# SERDES_10G0 register map
Vendor: Texas Instruments
Registers are 32-bit, read-write, reset 0x0 unless marked. A register's access mark holds for its fields unless they carry their own. Offsets are as the file gives them; [hi:lo] are bit positions; {n}, {i} and the like mark numbered series.

## SERDES_10G0 (part 2 of 5)
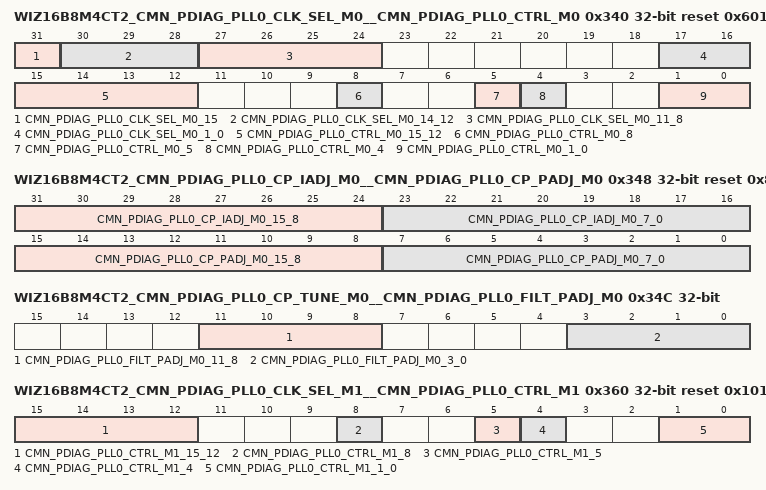
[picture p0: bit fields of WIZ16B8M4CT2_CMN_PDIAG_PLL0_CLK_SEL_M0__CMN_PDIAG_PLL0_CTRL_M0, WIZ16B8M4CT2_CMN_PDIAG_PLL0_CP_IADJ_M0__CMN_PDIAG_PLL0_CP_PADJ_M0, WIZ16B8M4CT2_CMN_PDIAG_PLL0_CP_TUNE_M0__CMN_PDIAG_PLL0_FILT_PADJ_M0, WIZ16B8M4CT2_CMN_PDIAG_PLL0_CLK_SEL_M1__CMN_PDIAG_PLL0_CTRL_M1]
0x340 WIZ16B8M4CT2_CMN_PDIAG_PLL0_CLK_SEL_M0__CMN_PDIAG_PLL0_CTRL_M0 reset 0x6011012 — PLL 0 control register mode 0
  [31] CMN_PDIAG_PLL0_CLK_SEL_M0_15 — PLL 0 clock 1 divider enable: This bit enables the divider used to generate the cmnda_pll0_clk_1, from the PLL high speed clock.
  [30:28] CMN_PDIAG_PLL0_CLK_SEL_M0_14_12 — PLL 0 clock 1 divider select: This field selects the divider value used to generate the cmnda_pll0_clk_1, from the PLL high speed clock, by driving the cmnda_pll0_clk_1_div_sel signal to the analog. The encoding of this signal is as follows. All codes currently result in divide by 16.
  [27:24] CMN_PDIAG_PLL0_CLK_SEL_M0_11_8 — PLL 0 clock 0 and derived reference clock divider select: This field selects the divider value used to generate the cmnda_pll0_clk_0 and derived reference clock, from the PLL high speed clock, by driving the cmnda_pll0_clk_0_div_sel signal to the analog. The encoding of this signal is as follows. Note that there are different divider values per bit for associated with each clock.
  [17:16] CMN_PDIAG_PLL0_CLK_SEL_M0_1_0 — PLL 0 clock select: This field selects one of 3 possible high speed output clocks from PLL 0, to drive on the high speed analog clock 0, by driving the cmnda_pll0_clk_sel signal to the analog. The encoding for this is as follows. 2'b00: Divide by 1 2'b01: Divide by 2 2'b10: Divide by 4 2'b11: Reserved
  [15:12] CMN_PDIAG_PLL0_CTRL_M0_15_12 — This field controls the Ring VCO Frequency drift with temperature. It controls the mix of vtref bias and external bias to keep the temperature drift for the ring low, by driving the cmnda_pll0_vco_ring_cmos_sel signal going into the common analog.
  [8] CMN_PDIAG_PLL0_CTRL_M0_8 — PLL VCO select: Selects the VCO mode of operation, by driving the cmnda_pll0_vco_sel signal going into the common analog. 1'b0: LC tank mode 1'b1: Ring oscillator mode
  [5] CMN_PDIAG_PLL0_CTRL_M0_5 — PLL feedback divider clock select: This signal selects which internal PLL clock will be used to drive the cmnda_pll0_fb_divider_clk, by driving the cmnda_pll0_fb_divider_clk_sel signal going into the common analog. 1'b0: Feedback divider clock 1'b1: PLL digital rate clock
  [4] CMN_PDIAG_PLL0_CTRL_M0_4 — PLL feedback divider pre-scale: controls the feedback divider pre-scale, by driving the cmnda_pll0_div24_sel signal going into the common analog. One should read the description of the PLL in section 10.4 Dual VCO PLL on page 420 for detailed information about the function of this divider control. 1'b0: Divide by 2 - When using the delta sigma modulator, this setting results in lower noise on the PLL output clock, but higher power. 1'b1: Divide by 4 - When using the delta sigma modulator, this setting results in higher noise on the PLL output clock, but lower power. This setting is ideal for cases when the delta sigma modulator is not used, because is results in both lower noise and lower power.
  [1:0] CMN_PDIAG_PLL0_CTRL_M0_1_0 — PLL PFD reset delay: Controls the minimum reset pulse width for the PFD. This drives the cmnda_pll0_pfd_rst_dly signal going into the common analog. The following lists the reset pulse width values for typical conditions for each of the possible values for this field. 2'b00 : Delay = 257.5 pSec (minimum) 2'b01 : Delay = 337.4 pSec 2'b10 : Delay = 415.2 pSec 2'b11 : Delay = 493.2 pSec (maximum)
0x348 WIZ16B8M4CT2_CMN_PDIAG_PLL0_CP_IADJ_M0__CMN_PDIAG_PLL0_CP_PADJ_M0 reset 0x8080028 — PLL 0 charge pump proportional path adjust register mode 0
  [31:24] CMN_PDIAG_PLL0_CP_IADJ_M0_15_8 — PLL charge pump integral path capacitance adjust: Adjusts the charge pump integral path capacitance, by driving the cmnda_pll0_cp_int_cap_adj signal going to the analog.
  [23:16] CMN_PDIAG_PLL0_CP_IADJ_M0_7_0 — PLL charge pump integral path current adjust: Adjusts the charge pump integral path current, by driving the cmnda_pll0_cp_int_cur_adj signal going to the analog.
  [15:8] CMN_PDIAG_PLL0_CP_PADJ_M0_15_8 — PLL charge pump proportional path capacitance adjust: Adjusts the charge pump proportional path capacitance, by driving the cmnda_pll0_cp_prop_cap_adj signal going to the analog.
  [7:0] CMN_PDIAG_PLL0_CP_PADJ_M0_7_0 — PLL charge pump proportional path current adjust: Adjusts the charge pump proportional path current, by driving the cmnda_pll0_cp_prop_cur_adj signal going to the analog.
0x34C WIZ16B8M4CT2_CMN_PDIAG_PLL0_CP_TUNE_M0__CMN_PDIAG_PLL0_FILT_PADJ_M0 — PLL 0 proportional path filter adjust register mode 0
  [11:8] CMN_PDIAG_PLL0_FILT_PADJ_M0_11_8 — PLL proportional path filter capacitance adjust: Adjusts the proportional path filter capacitance, by driving the cmnda_pll0_filt_c_adj signal going to the analog.
  [3:0] CMN_PDIAG_PLL0_FILT_PADJ_M0_3_0 — PLL proportional path filter resistance adjust: Adjusts the proportional path filter resistance, by driving the cmnda_pll0_filt_r_adj signal going to the analog.
0x360 WIZ16B8M4CT2_CMN_PDIAG_PLL0_CLK_SEL_M1__CMN_PDIAG_PLL0_CTRL_M1 reset 0x1012 — PLL 0 control register mode 1
  [15:12] CMN_PDIAG_PLL0_CTRL_M1_15_12 — This field controls the Ring VCO Frequency drift with temperature. It controls the mix of vtref bias and external bias to keep the temperature drift for the ring low, by driving the cmnda_pll0_vco_ring_cmos_sel signal going into the common analog.
  [8] CMN_PDIAG_PLL0_CTRL_M1_8 — PLL VCO select: Selects the VCO mode of operation, by driving the cmnda_pll0_vco_sel signal going into the common analog. 1'b0: LC tank mode 1'b1: Ring oscillator mode
  [5] CMN_PDIAG_PLL0_CTRL_M1_5 — PLL feedback divider clock select: This signal selects which internal PLL clock will be used to drive the cmnda_pll0_fb_divider_clk,driving the cmnda_pll0_fb_divider_clk_sel signal going into the common analog. 1'b0: Feedback divider clock 1'b1: PLL digital rate clock
  [4] CMN_PDIAG_PLL0_CTRL_M1_4 — PLL feedback divider pre-scale: controls the feedback divider pre-scale, by driving the cmnda_pll0_div24_sel signal going into the common analog. One should read the description of the PLL in section 10.4 Dual VCO PLL on page 420 for detailed information about the function of this divider control. 1'b0: Divide by 2 - When using the delta sigma modulator, this setting results in lower noise on the PLL output clock, but higher power. 1'b1: Divide by 4 - When using the delta sigma modulator, this setting results in higher noise on the PLL output clock, but lower power. This setting is ideal for cases when the delta sigma modulator is not used, because is results in both lower noise and lower power.
  [1:0] CMN_PDIAG_PLL0_CTRL_M1_1_0 — PLL PFD reset delay: Controls the minimum reset pulse width for the PFD. This drives the cmnda_pll0_pfd_rst_dly signal going into the common analog. The following lists the reset pulse width values for typical conditions for each of the possible values for this field. 2'b00 : Delay = 257.5 pSec (minimum) 2'b01 : Delay = 337.4 pSec 2'b10 : Delay = 415.2 pSec 2'b11 : Delay = 493.2 pSec (maximum)
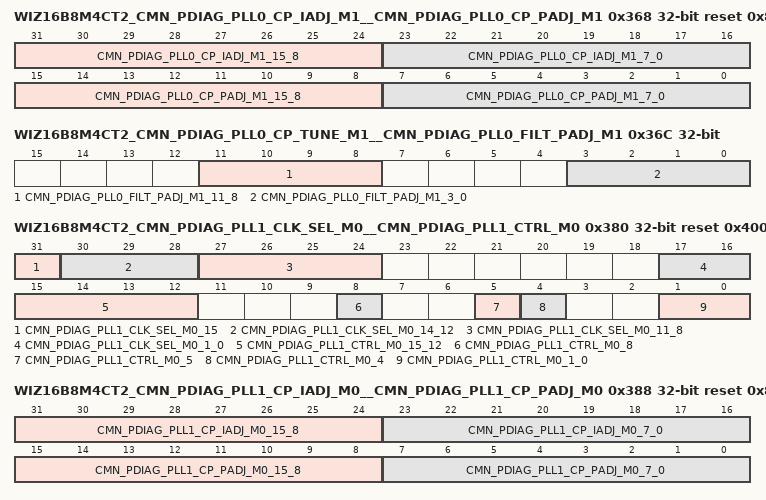
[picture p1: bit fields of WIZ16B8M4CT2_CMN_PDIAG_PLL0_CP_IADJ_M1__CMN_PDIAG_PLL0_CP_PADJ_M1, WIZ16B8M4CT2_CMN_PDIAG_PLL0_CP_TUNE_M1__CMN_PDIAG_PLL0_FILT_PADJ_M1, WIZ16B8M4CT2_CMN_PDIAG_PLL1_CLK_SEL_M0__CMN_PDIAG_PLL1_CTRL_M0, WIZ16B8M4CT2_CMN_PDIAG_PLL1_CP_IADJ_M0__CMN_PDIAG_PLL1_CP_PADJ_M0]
0x368 WIZ16B8M4CT2_CMN_PDIAG_PLL0_CP_IADJ_M1__CMN_PDIAG_PLL0_CP_PADJ_M1 reset 0x8080128 — PLL 0 charge pump proportional path adjust register mode 1
  [31:24] CMN_PDIAG_PLL0_CP_IADJ_M1_15_8 — PLL charge pump integral path capacitance adjust: Adjusts the charge pump integral path capacitance, by driving the cmnda_pll0_cp_int_cap_adj signal going to the analog.
  [23:16] CMN_PDIAG_PLL0_CP_IADJ_M1_7_0 — PLL charge pump integral path current adjust: Adjusts the charge pump integral path current, by driving the cmnda_pll0_cp_int_cur_adj signal going to the analog.
  [15:8] CMN_PDIAG_PLL0_CP_PADJ_M1_15_8 — PLL charge pump proportional path capacitance adjust: Adjusts the charge pump proportional path capacitance, by driving the cmnda_pll0_cp_prop_cap_adj signal going to the analog.
  [7:0] CMN_PDIAG_PLL0_CP_PADJ_M1_7_0 — PLL charge pump proportional path current adjust: Adjusts the charge pump proportional path current, by driving the cmnda_pll0_cp_prop_cur_adj signal going to the analog.
0x36C WIZ16B8M4CT2_CMN_PDIAG_PLL0_CP_TUNE_M1__CMN_PDIAG_PLL0_FILT_PADJ_M1 — PLL 0 proportional path filter adjust register mode 1
  [11:8] CMN_PDIAG_PLL0_FILT_PADJ_M1_11_8 — PLL proportional path filter capacitance adjust: Adjusts the proportional path filter capacitance, by driving the cmnda_pll0_filt_c_adj signal going to the analog.
  [3:0] CMN_PDIAG_PLL0_FILT_PADJ_M1_3_0 — PLL proportional path filter resistance adjust: Adjusts the proportional path filter resistance, by driving the cmnda_pll0_filt_r_adj signal going to the analog.
0x380 WIZ16B8M4CT2_CMN_PDIAG_PLL1_CLK_SEL_M0__CMN_PDIAG_PLL1_CTRL_M0 reset 0x4001012 — PLL 1 control register mode 0
  [31] CMN_PDIAG_PLL1_CLK_SEL_M0_15 — PLL 1 clock 1 divider enable: This bit enables the divider used to generate the cmnda_pll1_clk_1, from the PLL high speed clock.
  [30:28] CMN_PDIAG_PLL1_CLK_SEL_M0_14_12 — PLL 1 clock 1 divider select: This field selects the divider value used to generate the cmnda_pll1_clk_1, from the PLL high speed clock, by driving the cmnda_pll1_clk_1_div_sel signal to the analog. The encoding of this signal is as follows. All codes currently result in divide by 16.
  [27:24] CMN_PDIAG_PLL1_CLK_SEL_M0_11_8 — PLL 1 clock 0 and derived reference clock divider select: This field selects the divider value used to generate the cmnda_pll1_clk_0 and derived reference clock, from the PLL high speed clock, by driving the cmnda_pll1_clk_0_div_sel signal to the analog. The encoding of this signal is as follows. Note that there are different divider values per bit for associated with each clock.
  [17:16] CMN_PDIAG_PLL1_CLK_SEL_M0_1_0 — PLL 1 clock select: This field selects one of 3 possible high speed output clocks from PLL 1, to drive on the high speed analog clock 1, by driving the cmnda_pll1_clk_sel signal to the analog. The encoding for this is as follows. 2'b00: Divide by 1 2'b01: Divide by 2 2'b10: Divide by 4 2'b11: Reserved
  [15:12] CMN_PDIAG_PLL1_CTRL_M0_15_12 — This field controls the Ring VCO Frequency drift with temperature. It controls the mix of vtref bias and external bias to keep the temperature drift for the ring low, by driving the cmnda_pll1_vco_ring_cmos_sel signal going into the common analog.
  [8] CMN_PDIAG_PLL1_CTRL_M0_8 — PLL VCO select: Selects the VCO mode of operation, by driving the cmnda_pll1_vco_sel signal going into the common analog. 1'b0: LC tank mode 1'b1: Ring oscillator mode
  [5] CMN_PDIAG_PLL1_CTRL_M0_5 — PLL feedback divider clock select: This signal selects which internal PLL clock will be used to drive the cmnda_pll1_fb_divider_clk,driving the cmnda_pll1_fb_divider_clk_sel signal going into the common analog. 1'b0: Feedback divider clock 1'b1: PLL digital rate clock
  [4] CMN_PDIAG_PLL1_CTRL_M0_4 — PLL feedback divider pre-scale: controls the feedback divider pre-scale, by driving the cmnda_pll1_div24_sel signal going into the common analog. One should read the description of the PLL in section 10.4 Dual VCO PLL on page 420 for detailed information about the function of this divider control. 1'b0: Divide by 2 - When using the delta sigma modulator, this setting results in lower noise on the PLL output clock, but higher power. 1'b1: Divide by 4 - When using the delta sigma modulator, this setting results in higher noise on the PLL output clock, but lower power. This setting is ideal for cases when the delta sigma modulator is not used, because is results in both lower noise and lower power.
  [1:0] CMN_PDIAG_PLL1_CTRL_M0_1_0 — PLL PFD reset delay: Controls the minimum reset pulse width for the PFD. This drives the cmnda_pll1_pfd_rst_dly signal going into the common analog. The following lists the reset pulse width values for typical conditions for each of the possible values for this field. 2'b00 : Delay = 257.5 pSec (minimum) 2'b01 : Delay = 337.4 pSec 2'b10 : Delay = 415.2 pSec 2'b11 : Delay = 493.2 pSec (maximum)
0x388 WIZ16B8M4CT2_CMN_PDIAG_PLL1_CP_IADJ_M0__CMN_PDIAG_PLL1_CP_PADJ_M0 reset 0x8080128 — PLL 1 charge pump proportional path adjust register mode 0
  [31:24] CMN_PDIAG_PLL1_CP_IADJ_M0_15_8 — PLL charge pump integral path capacitance adjust: Adjusts the charge pump integral path capacitance, by driving the cmnda_pll1_cp_int_cap_adj signal going to the analog.
  [23:16] CMN_PDIAG_PLL1_CP_IADJ_M0_7_0 — PLL charge pump integral path current adjust: Adjusts the charge pump integral path current, by driving the cmnda_pll1_cp_int_cur_adj signal going to the analog.
  [15:8] CMN_PDIAG_PLL1_CP_PADJ_M0_15_8 — PLL charge pump proportional path capacitance adjust: Adjusts the charge pump proportional path capacitance, by driving the cmnda_pll1_cp_prop_cap_adj signal going to the analog.
  [7:0] CMN_PDIAG_PLL1_CP_PADJ_M0_7_0 — PLL charge pump proportional path current adjust: Adjusts the charge pump proportional path current, by driving the cmnda_pll0_cp_prop_cur_adj signal going to the analog.
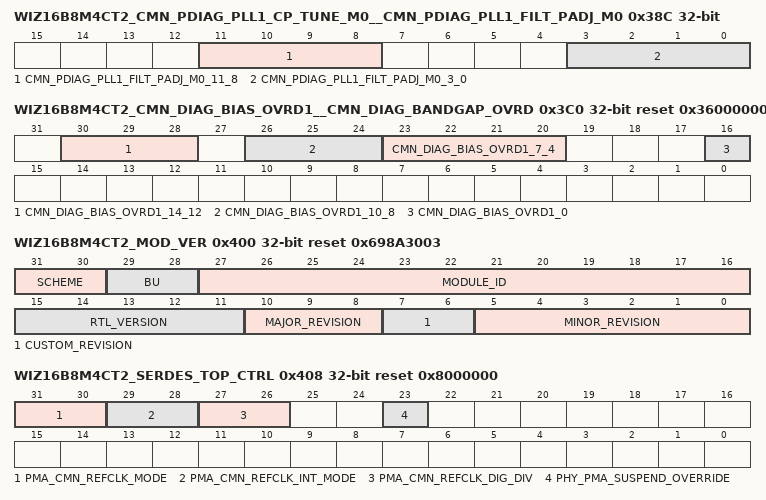
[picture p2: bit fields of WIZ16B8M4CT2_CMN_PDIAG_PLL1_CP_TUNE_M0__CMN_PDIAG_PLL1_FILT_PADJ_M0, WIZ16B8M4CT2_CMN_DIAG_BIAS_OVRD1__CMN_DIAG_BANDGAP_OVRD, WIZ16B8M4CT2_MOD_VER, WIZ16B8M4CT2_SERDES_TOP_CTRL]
0x38C WIZ16B8M4CT2_CMN_PDIAG_PLL1_CP_TUNE_M0__CMN_PDIAG_PLL1_FILT_PADJ_M0 — PLL 1 proportional path filter adjust register mode 0
  [11:8] CMN_PDIAG_PLL1_FILT_PADJ_M0_11_8 — PLL proportional path filter capacitance adjust: Adjusts the proportional path filter capacitance, by driving the cmnda_pll1_filt_c_adj signal going to the analog.
  [3:0] CMN_PDIAG_PLL1_FILT_PADJ_M0_3_0 — PLL proportional path filter resistance adjust: Adjusts the proportional path filter resistance, by driving the cmnda_pll1_filt_r_adj signal going to the analog.
0x3C0 WIZ16B8M4CT2_CMN_DIAG_BIAS_OVRD1__CMN_DIAG_BANDGAP_OVRD reset 0x36000000 — Bandgap override register
  [30:28] CMN_DIAG_BIAS_OVRD1_14_12 — Receiver resistor calibration current adjust: This field is used to adjust the receiver resistor calibration bias current. It drives the cmnda_bias_rx_rescal_adj signal going to the analog. The following list shows the encoding of this field. 3'b000 : 110.72 uA 3'b001 : 112.50 uA 3'b010 : 114.29 uA 3'b011 : 116.07 uA 3'b100 : 117.86 uA 3'b101 : 119.64 uA 3'b110 : 121.43 uA 3'b111 : 123.22 uA
  [26:24] CMN_DIAG_BIAS_OVRD1_10_8 — Transmitter resistor calibration current adjust: This field is used to adjust the transmitter resistor calibration bias current. It drives the cmnda_bias_tx_rescal_adj signal going to the analog. The following list shows the encoding of this field. 3'b000 : 110.72 uA 3'b001 : 112.50 uA 3'b010 : 114.29 uA 3'b011 : 116.07 uA 3'b100 : 117.86 uA 3'b101 : 119.64 uA 3'b110 : 121.43 uA 3'b111 : 123.22 uA
  [23:20] CMN_DIAG_BIAS_OVRD1_7_4 — Reserved - spare
  [16] CMN_DIAG_BIAS_OVRD1_0 — Reserved - spare
0x400 WIZ16B8M4CT2_MOD_VER ro reset 0x698A3003 — The Module and Version Register identifies the module identifier and revision of the WIZ16B8M4CT2 module.
  [31:30] SCHEME — Module Scheme
  [29:28] BU — Module Business Unit
  [27:16] MODULE_ID — WIZ16B8M4CT2 module ID.
  [15:11] RTL_VERSION
  [10:8] MAJOR_REVISION
  [7:6] CUSTOM_REVISION
  [5:0] MINOR_REVISION
0x404 WIZ16B8M4CT2_SERDES_CTRL — Sets the SERDES control state.
  [31] POR_EN — The por_en allows the system to place the SERDES in a reset state, Access to the SERDES registers are ignored.
0x408 WIZ16B8M4CT2_SERDES_TOP_CTRL reset 0x8000000 — The SERDES Top Level Control
  [31:30] PMA_CMN_REFCLK_MODE — The PMA common differential reference clock mode - Sets the mode of operation for differential reference clock input. Must be set before the de-assertion of apb_preset_n/phy_reset_n. 2'b00 - 100 MHz and greater differential reference clock. 2'b01 - 100 MHz and greater singled ended DC coupled test reference clock. 2'b10 - Less than 100 MHz differential reference clock. 2'b11 - Less than 100 MHz single ended DC coupled test reference clock.
  [29:28] PMA_CMN_REFCLK_INT_MODE — The PMA common internal reference clock mode - Sets the mode of operation for internal reference clock input. Must be set before the de-assertion of apb_preset_n/phy_reset_n. 2'b00 - Reserved 2'b01 - 100 MHz and greater reference clock 2'b10 - Reserved 2'b11 - Less than 100 MHz reference clock
  [27:26] PMA_CMN_REFCLK_DIG_DIV — The PMA common reference clock digital divide ratio select - Must be set before the de-assertion of apb_preset_n/phy_reset_n. 2'b00 - Divide by 1 (set for reference clock in the 19.2 to 27MHz range) 2'b01 - Divide by 2 (Reserved) 2'b10 - Divide by 4 (set for 100 MHz reference clock) 2'b11 - Divide by 8 (Reserved)
  [23] PHY_PMA_SUSPEND_OVERRIDE — The PHY PMA common suspend override enable: 1 = disables suspending the PMA common when all links are in low power state (L1 SS, PCIe P2, USB P3, power down disabled, etc.). 0 = PMA common will be suspended when all links are in low power state. Driving this pin high has no effect if the PMA common is already suspended or is in the process of being suspended (i.e. it will not force the PMA common to resume). It only prevents the start of suspending the PMA common. However, if this pin is de-asserted when all links are in low power state, the PMA common will then be suspended.
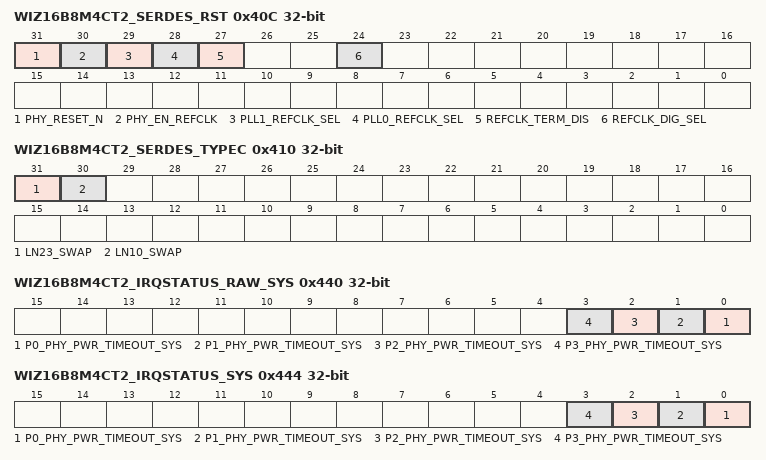
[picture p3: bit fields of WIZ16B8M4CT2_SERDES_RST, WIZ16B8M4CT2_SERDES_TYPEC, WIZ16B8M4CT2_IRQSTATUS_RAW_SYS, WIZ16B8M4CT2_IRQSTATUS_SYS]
0x40C WIZ16B8M4CT2_SERDES_RST — The SERDES Reset Register controls the Phy reset and REFCLK selection for the SERDES.
  [31] PHY_RESET_N — The PHY reset : Asserting this signal low will reset all PHY logic for the entire PHY with the exception of the APB registers and TAP controller. Note: Upon de-assertion, all PHY inputs must be driven as described in the PIPE specification for a PIPE reset.
  [30] PHY_EN_REFCLK — The PHY reference clock enable: When cmn_refclk_<p/m> is configured as a reference clock output, 1 = glitch-less enable of the reference clock output. 0 = glitch-less turn off reference clock output. Used in L1.x entry/exit protocol. Note: When outputting a derived reference clock from the PLL, it is recommended to drive phy_en_refclk low until the PHY has completed start-up and de-asserted pipe_l*_reset_ n for PIPE operation or asserted cmn_ready for Raw SERDES operation.. The clock will not be 'good' until the PHY has completed initial start-up.
  [29] PLL1_REFCLK_SEL — The PMA common PLL1 reference clock source select - 0 - Selects cmn_refclk_<m/p> as reference clock source 1 - Selects pma_cmn_refclk_int as reference clock source. Note: This field is write protected when register field ~iphy_reset_n is a '1'.
  [28] PLL0_REFCLK_SEL — The PMA common PLL0 reference clock source select - 0 - Selects cmn_refclk_<m/p> as reference clock source 1 - Selects pma_cmn_refclk_int as reference clock source. Note: This field is write protected when register field ~iphy_reset_n is a '1'.
  [27] REFCLK_TERM_DIS — The PMA common differential reference clock termination disable - enables/disables termination for difference reference clock input (cmn_refclk_<p/m>). Must be set before the de-assertion of apb_preset_n/phy_reset_n. 1 = termination disabled 0 = termination enabled. Note: This field is write protected when register field ~iphy_reset_n is a '1'.
  [24] REFCLK_DIG_SEL — The PMA common reference clock select - Selects the reference clock source for the digital logic between cmn_refclk_<p/m> and pma_cmn_refclk_int. Must be set before the de-assertion of apb_preset_n/phy_reset_n. 0 - cmn_refclk_<p/m> 1 - pma_cmn_refclk_int. Note: This field is write protected when register field ~iphy_reset_n is a '1'.
0x410 WIZ16B8M4CT2_SERDES_TYPEC — The SERDES Type C control register allows the external lanes selection to be swapped.
  [31] LN23_SWAP — The~iln23_swap will swap the lanes 2 and 3. That is all control for lane 2 will apply to lane 3 and vice versa. You cannot set ~iln23_swap to swap lanes in a link. That is If lanes 2 and 3 are used for a single link of PCIe, the ~iln23_swap must be '0'. Note: This field is write protected when register field ~i(reg_p2_enable|reg_p3_enable) is a '1'.
  [30] LN10_SWAP — The ~iln10_swap will swap the lanes 0 and 1. That is all control for lane 0 will apply to lane 1 and vice versa. You cannot set ~iln10_swap to swap lanes in a link. That is If lanes 0 and 1 are used for a single link of PCIe, the ~iln10_swap must be '0'. Note: This field is write protected when register field ~i(reg_p0_enable|reg_p1_enable) is a '1'.
0x440 WIZ16B8M4CT2_IRQSTATUS_RAW_SYS access not given — The System Interrupt Raw Status Register holds the raw status of the SERDES power timout interrupts.
  [n] P{n}_PHY_PWR_TIMEOUT_SYS (n=0..3) — Phy Power Timeout occured for lane {n} error. That is the lane power state took too long to occur.. Write 1 to clear the status after interrupt has been serviced (raw status gets cleared, i.e. even if not enabled). Writing a 0 has no effect. (access R/W1TS)
0x444 WIZ16B8M4CT2_IRQSTATUS_SYS access not given — The System Interrupt Status Register holds the masked status for the SERDES power timout interrupts.
  [n] P{n}_PHY_PWR_TIMEOUT_SYS (n=0..3) — Phy Power Timeout occured for lane {n} error. That is the lane power state took too long to occur.. Write 1 to clear the status after interrupt has been serviced (raw status gets cleared, i.e. even if not enabled). Writing a 0 has no effect. (access R/W1TC)
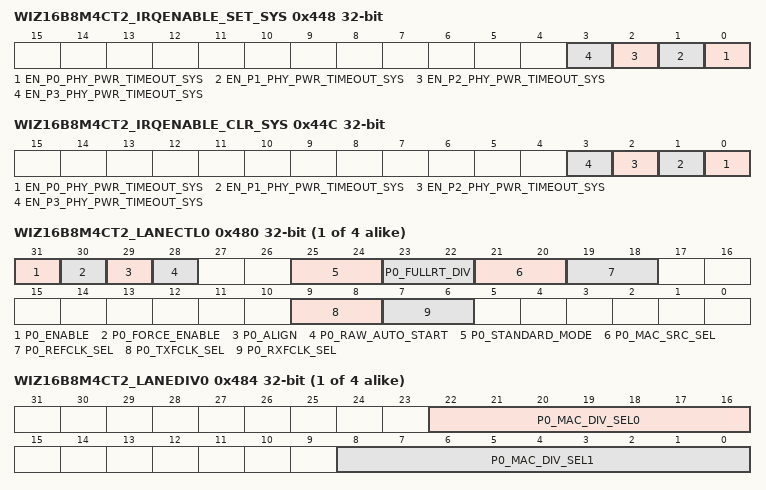
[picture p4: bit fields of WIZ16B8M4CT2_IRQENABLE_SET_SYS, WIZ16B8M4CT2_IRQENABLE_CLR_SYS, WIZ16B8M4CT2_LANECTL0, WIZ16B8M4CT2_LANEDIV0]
0x448 WIZ16B8M4CT2_IRQENABLE_SET_SYS access not given — The System Interrupt Enable Set Register holds the interrupt enable status of the SERDES power timout interrupts.
  [n] EN_P{n}_PHY_PWR_TIMEOUT_SYS (n=0..3) — Interrupt Enable set for Phy Power Timeout for lane {n} error. Writing a 1 will enable the interrupt, and set this bit as well as the corresponding Interrupt Enable Set Register. Writing a 0 has no effect. (access R/W1TS)
0x44C WIZ16B8M4CT2_IRQENABLE_CLR_SYS access not given — The System Interrupt Enable Clear Register holds the interrupt enable status of the SERDES power timout interrupts.
  [n] EN_P{n}_PHY_PWR_TIMEOUT_SYS (n=0..3) — Interrupt Enable clear for Phy Power Timeout for lane {n} error. Writing a 1 will disable the interrupt, and clear this bit as well as the corresponding Interrupt Enable Set Register. Writing a 0 has no effect. (access R/W1TC)
{0x480+0x40*i} WIZ16B8M4CT2_LANECTL{i} (i=0..3) — The Lane Control Register sets the lane specific modes of operation.
  [31] P{i}_ENABLE — The p{i}_enable is AND'd with the IPx_LNy_reset_n to enable the lane.
  [30] P{i}_FORCE_ENABLE — The p{i}_force_enable is OR'd with the IPx_LNy_reset_n to force enable the lane.
  [29] P{i}_ALIGN — The p{i}_align will auto align the RAW interface to 8B10B comma characters.
  [28] P{i}_RAW_AUTO_START — The p{i}_raw_auto_start will auto sequence the RAW interface according to the configuration settings
  [25:24] P{i}_STANDARD_MODE — Standard Mode specified by Cadence.
  [23:22] P{i}_FULLRT_DIV — Full Rate divider for 2x MAC speed mode. The PMA PLL full rate clock divider select - divide ratio for pma_pllclk_fullrt_ln_*. 00 = Divide by 1 01 = Divide by 2 10 = Divide by 4 11 = Divide by 8
  [21:20] P{i}_MAC_SRC_SEL — MAC clock source select : Selects which PMA clock to use as clock souse for pcs_mac_clk*_ln_*. 2'b00 - PMA output xcvr_pll_clk_datart_ln_* for the associated lane. 2'b01 - PMA output xcvr_pll_clk_fullrt_ln_* for the associated lane. 2'b10 - PMA output cmn_ref_clk_rcv. 2'b11 - Reserved
  [19:18] P{i}_REFCLK_SEL — Refclk Select determines which clocks will be used for the IP refclk signal. 0 - pma_pllclk_fullrt_ln_{i} is used. 1 - pcs_mac_clk_ln_{i} is used. 2 - pcs_mac_clk_divx0_ln_{i} is used. 3 - pcs_mac_clk_divx1_ln_{i} is used.
  [9:8] P{i}_TXFCLK_SEL — Fclk Select determines which clocks will be used for the IP txfclk signal. 0 - pma_pllclk_fullrt_ln_{i} is used. 1 - pcs_mac_clk_ln_{i} is used. 2 - pcs_mac_clk_divx0_ln_{i} is used. 3 - pcs_mac_clk_divx1_ln_{i} is used.
  [7:6] P{i}_RXFCLK_SEL — Fclk Select determines which clocks will be used for the IP rxfclk signal. 0 - pma_rx_rd_clk2x_ln_{i} is used. 1 - pma_rx_rd_clk_ln_{i} is used. 2 - rd_div2_clk{i} is used. 3 - rd_div4_clk{i} is used.
{0x484+0x40*i} WIZ16B8M4CT2_LANEDIV{i} (i=0..3) — The Lane Divider Register sets the lane specific dividers of
  [22:16] P{i}_MAC_DIV_SEL0 — The ~ip{i}_mac_div_sel0 controls the divider for lane {i} MAC clock divider ratio select : Selects the divider ratio for pcs_mac_clk_divx0_ln_*. 7'd0 : Reserved 7'd1 : Divide by 1 7'd2 : Divide by 2 7'd3 : Divide by 3 ... 7'dn : Divide by n n = 127 (maximum)
  [8:0] P{i}_MAC_DIV_SEL1 — The ~ip{i}_mac_div_sel1 controls the divider for lane {i} MAC clock divider ratio select : Selects the divider ratio for pcs_mac_clk_divx1_ln_*. 9'd0 : Reserved 9'd1 : Divide by 1 9'd2 : Divide by 2 9'd3 : Divide by 3 ... 9'dn : Divide by n n = 511 (maximum)
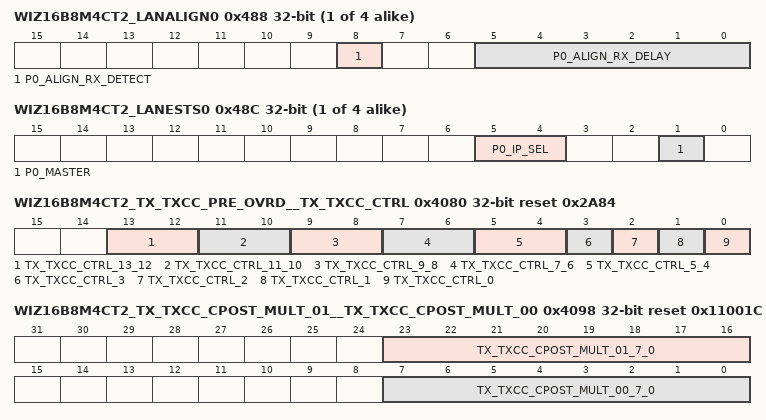
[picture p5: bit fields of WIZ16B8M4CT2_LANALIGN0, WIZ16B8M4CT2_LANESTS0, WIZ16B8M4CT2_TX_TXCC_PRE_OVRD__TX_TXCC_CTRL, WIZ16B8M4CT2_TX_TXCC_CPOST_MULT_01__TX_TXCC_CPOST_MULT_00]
{0x488+0x40*i} WIZ16B8M4CT2_LANALIGN{i} ro (i=0..3) — The Lane Align reports the 8B10B alignment delay from the Comma aligner when 8B10B protocol is used in RAW mode.
  [8] P{i}_ALIGN_RX_DETECT — The ~ip{i}_align_rx_detect indicates that alignment has happened and The ~ip{i}_align_rx_delay is valid.
  [5:0] P{i}_ALIGN_RX_DELAY — The ~ip{i}_align_rx_delay indicates the number of bits that are added to align the data to an 8B10B alignment. This value should be added to the latency of the receiver so that an accurate time of Time Sync packets can be calculated.
{0x48C+0x40*i} WIZ16B8M4CT2_LANESTS{i} ro (i=0..3) — The lane Status reports the lane state information for debug purposes.
  [5:4] P{i}_IP_SEL — The ~ip{i}_ip_sel indicates the current IP lane selection for the lane.
  [1] P{i}_MASTER — The ~ip{i}_master indicates the lane is a base lane for a multi lane link. When '1' Lane is lane 0 of a multi lane link, When '0' lane is part of a multi lane link.
0x5F8 WIZ16B8M4CT2_DTB_MUX_SEL — The digital test bus mux select determines the value on the test bus.
  [4:0] DTB_MUX_SEL — See cadence documentation on digital test bus.
0x5FC WIZ16B8M4CT2_DIAG_TEST — The Diagnostic Test Register allows the system to validate the read and write of all data bits.
  [31:0] DIAG_REG — Diagnostic register. This register allows full read/write of all data bits to be tested.
0x2000 WIZ16B8M4CT2_RESERVEDBIT13ADDRESSA — Reserved Address bit 13 area A
  [31:0] RES_BIT13_ADR_A — Write only test region A
0x4080 WIZ16B8M4CT2_TX_TXCC_PRE_OVRD__TX_TXCC_CTRL reset 0x2A84 — TX coefficient controller control register
  [13:12] TX_TXCC_CTRL_13_12 — Margin multiplier rounding control: This field controls the rounding function on the margin multiplier. 2'b00 : Round to nearest integer 2'b01 : Floor 2'b10 : Ceiling
  [11:10] TX_TXCC_CTRL_11_10 — LF value multiplier rounding control: This field controls the rounding function on the LF value multiplier. 2'b00 : Round to nearest integer 2'b01 : Floor 2'b10 : Ceiling
  [9:8] TX_TXCC_CTRL_9_8 — Calculated post-emphasis multiplier rounding control: This field controls the rounding function on the calculated post-emphasis multiplier. 2'b00 : Round to nearest integer 2'b01 : Floor 2'b10 : Ceiling
  [7:6] TX_TXCC_CTRL_7_6 — Calculated pre-emphasis multiplier rounding control: This field controls the rounding function on the pre-emphasis multiplier. 2'b00 : Round to nearest integer 2'b01 : Floor 2'b10 : Ceiling
  [5:4] TX_TXCC_CTRL_5_4 — Coefficient calculator multiplier rounding control: This field controls the rounding function on the coefficient calculator multiplier. 2'b00 : Round to nearest integer 2'b01 : Floor 2'b10 : Ceiling
  [3] TX_TXCC_CTRL_3 — De-emphasis control standard mode 3 value: This bit controls the de-emphasis mode when the xcvr_standard_mode is set to 2'b11. 1'b0 : Use the calculated de-emphasis values based on the 2 least significant bits of the top level tx_deemphasis signal. 1'b1 : Use the coefficient values on all 18 bits of the top level tx_deemphasis signal.
  [2] TX_TXCC_CTRL_2 — De-emphasis control standard mode 2 value: This bit controls the de-emphasis mode when the xcvr_standard_mode is set to 2'b10. 1'b0 : Use the calculated de-emphasis values based on the 2 least significant bits of the top level tx_deemphasis signal. 1'b1 : Use the coefficient values on all 18 bits of the top level tx_deemphasis signal.
  [1] TX_TXCC_CTRL_1 — De-emphasis control standard mode 1 value: This bit controls the de-emphasis mode when the xcvr_standard_mode is set to 2'b01. 1'b0 : Use the calculated de-emphasis values based on the 2 least significant bits of the top level tx_deemphasis signal. 1'b1 : Use the coefficient values on all 18 bits of the top level tx_deemphasis signal.
  [0] TX_TXCC_CTRL_0 — De-emphasis control standard mode 0 value: This bit controls the de-emphasis mode when the xcvr_standard_mode is set to 2'b00. 1'b0 : Use the calculated de-emphasis values based on the 2 least significant bits of the top level tx_deemphasis signal. 1'b1 : Use the coefficient values on all 18 bits of the top level tx_deemphasis signal.
0x4098 WIZ16B8M4CT2_TX_TXCC_CPOST_MULT_01__TX_TXCC_CPOST_MULT_00 reset 0x11001C — Calculated post emphasis multiplier value 00 register
  [23:16] TX_TXCC_CPOST_MULT_01_7_0 — Calculated post emphasis multiplier value 01: The value in this field specifies the multiplier value used to generate the calculated post emphasis value from the FS value when tx_deemphasis[1:0] = 2'b01. The following describes the multiplier value each bit in this field corresponds to. Bit 7 : 128/128 = 1.000000 Bit 6 : 64/128 = 0.500000 Bit 5 : 32/128 = 0.250000 Bit 4 : 16/128 = 0.125000 Bit 3 : 8/128 = 0.062500 Bit 2 : 4/128 = 0.031250 Bit 1 : 2/128 = 0.015625 Bit 0 : 1/128 = 0.0078125 Note that the output of the multiplier is 6 bits wide. It is possible to set the multiplier value here to a sufficiently large value to cause the multiplier result to be such that it can't be represented by a 6 bit value. In such a case, the multiplier output will be driven to 6'b111111.
  [7:0] TX_TXCC_CPOST_MULT_00_7_0 — Calculated post emphasis multiplier value 00: The value in this field specifies the multiplier value used to generate the calculated post emphasis value from the FS value when tx_deemphasis[1:0] = 2'b00. The following describes the multiplier value each bit in this field corresponds to. Bit 7 : 128/128 = 1.000000 Bit 6 : 64/128 = 0.500000 Bit 5 : 32/128 = 0.250000 Bit 4 : 16/128 = 0.125000 Bit 3 : 8/128 = 0.062500 Bit 2 : 4/128 = 0.031250 Bit 1 : 2/128 = 0.015625 Bit 0 : 1/128 = 0.0078125 Note that the output of the multiplier is 6 bits wide. It is possible to set the multiplier value here to a sufficiently large value to cause the multiplier result to be such that it can't be represented by a 6 bit value. In such a case, the multiplier output will be driven to 6'b111111.
0x40A0 WIZ16B8M4CT2_TX_TXCC_MGNFS_MULT_001__TX_TXCC_MGNFS_MULT_000 — Margin full swing multiplier value 000 register
  [7:0] TX_TXCC_MGNFS_MULT_000_7_0 — Margin full swing multiplier value 000: The value in this field specifies the multiplier value used to generate the margin value from the resistor calibration value when tx_vmargin = 3'b000 and tx_low_power_swing_en = 1'b0. The following describes the multiplier value each bit in this field corresponds to. Bit 7 : 128/128 = 1.000000 Bit 6 : 64/128 = 0.500000 Bit 5 : 32/128 = 0.250000 Bit 4 : 16/128 = 0.125000 Bit 3 : 8/128 = 0.062500 Bit 2 : 4/128 = 0.031250 Bit 1 : 2/128 = 0.015625 Bit 0 : 1/128 = 0.0078125 Note that the largest value this is allowed to be set to is 54/128. Note that the output of the multiplier is 6 bits wide. It is possible to set the multiplier value here to a sufficiently large value to cause the multiplier result to be such that it can't be represented by a 6 bit value. In such a case, the multiplier output will be driven to 6'b111111.
0x40C8 WIZ16B8M4CT2_TX_TXCC_P5PRE_COEF_MULT__TX_TXCC_P4PRE_COEF_MULT reset 0xD0000 — Preset 4 pre emphasis coefficient multiplier value register
  [23:16] TX_TXCC_P5PRE_COEF_MULT_7_0 — Preset 5 pre emphasis coefficient multiplier value : The value in this field specifies the multiplier value used to generate the preset 5 pre emphasis coefficient value from the FS value. The following describes the multiplier value each bit in this field corresponds to. Bit 7 : 128/128 = 1.000000 Bit 6 : 64/128 = 0.500000 Bit 5 : 32/128 = 0.250000 Bit 4 : 16/128 = 0.125000 Bit 3 : 8/128 = 0.062500 Bit 2 : 4/128 = 0.031250 Bit 1 : 2/128 = 0.015625 Bit 0 : 1/128 = 0.0078125 Note that the output of the multiplier is 6 bits wide. It is possible to set the multiplier value here to a sufficiently large value to cause the multiplier result to be such that it can't be represented by a 6 bit value. In such a case, the multiplier output will be driven to 6'b111111.
0x40CC WIZ16B8M4CT2_TX_TXCC_P7PRE_COEF_MULT__TX_TXCC_P6PRE_COEF_MULT reset 0xD0000 — Preset 6 pre emphasis coefficient multiplier value register
  [23:16] TX_TXCC_P7PRE_COEF_MULT_7_0 — Preset 7 pre emphasis coefficient multiplier value : The value in this field specifies the multiplier value used to generate the preset 7 pre emphasis coefficient value from the FS value. The following describes the multiplier value each bit in this field corresponds to. Bit 7 : 128/128 = 1.000000 Bit 6 : 64/128 = 0.500000 Bit 5 : 32/128 = 0.250000 Bit 4 : 16/128 = 0.125000 Bit 3 : 8/128 = 0.062500 Bit 2 : 4/128 = 0.031250 Bit 1 : 2/128 = 0.015625 Bit 0 : 1/128 = 0.0078125 Note that the output of the multiplier is 6 bits wide. It is possible to set the multiplier value here to a sufficiently large value to cause the multiplier result to be such that it can't be represented by a 6 bit value. In such a case, the multiplier output will be driven to 6'b111111.
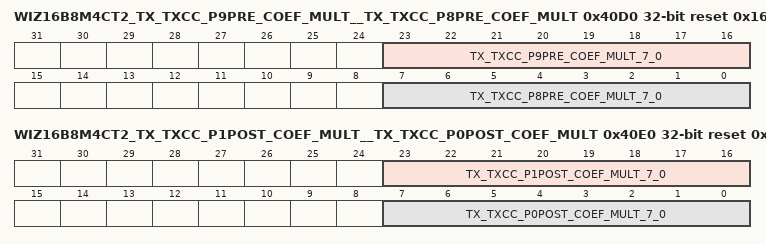
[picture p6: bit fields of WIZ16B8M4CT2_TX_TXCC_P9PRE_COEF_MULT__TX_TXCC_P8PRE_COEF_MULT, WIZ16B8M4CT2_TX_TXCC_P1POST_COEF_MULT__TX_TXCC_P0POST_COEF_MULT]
0x40D0 WIZ16B8M4CT2_TX_TXCC_P9PRE_COEF_MULT__TX_TXCC_P8PRE_COEF_MULT reset 0x160010 — Preset 8 pre emphasis coefficient multiplier value register
  [23:16] TX_TXCC_P9PRE_COEF_MULT_7_0 — Preset 9 pre emphasis coefficient multiplier value : The value in this field specifies the multiplier value used to generate the preset 9 pre emphasis coefficient value from the FS value. The following describes the multiplier value each bit in this field corresponds to. Bit 7 : 128/128 = 1.000000 Bit 6 : 64/128 = 0.500000 Bit 5 : 32/128 = 0.250000 Bit 4 : 16/128 = 0.125000 Bit 3 : 8/128 = 0.062500 Bit 2 : 4/128 = 0.031250 Bit 1 : 2/128 = 0.015625 Bit 0 : 1/128 = 0.0078125 Note that the output of the multiplier is 6 bits wide. It is possible to set the multiplier value here to a sufficiently large value to cause the multiplier result to be such that it can't be represented by a 6 bit value. In such a case, the multiplier output will be driven to 6'b111111.
  [7:0] TX_TXCC_P8PRE_COEF_MULT_7_0 — Preset 8 pre emphasis coefficient multiplier value : The value in this field specifies the multiplier value used to generate the preset 8 pre emphasis coefficient value from the FS value. The following describes the multiplier value each bit in this field corresponds to. Bit 7 : 128/128 = 1.000000 Bit 6 : 64/128 = 0.500000 Bit 5 : 32/128 = 0.250000 Bit 4 : 16/128 = 0.125000 Bit 3 : 8/128 = 0.062500 Bit 2 : 4/128 = 0.031250 Bit 1 : 2/128 = 0.015625 Bit 0 : 1/128 = 0.0078125 Note that the output of the multiplier is 6 bits wide. It is possible to set the multiplier value here to a sufficiently large value to cause the multiplier result to be such that it can't be represented by a 6 bit value. In such a case, the multiplier output will be driven to 6'b111111.
0x40E0 WIZ16B8M4CT2_TX_TXCC_P1POST_COEF_MULT__TX_TXCC_P0POST_COEF_MULT reset 0x160022 — Preset 0 post emphasis coefficient multiplier value register
  [23:16] TX_TXCC_P1POST_COEF_MULT_7_0 — Preset 1 post emphasis coefficient multiplier value : The value in this field specifies the multiplier value used to generate the preset 1 post emphasis coefficient value from the FS value. The following describes the multiplier value each bit in this field corresponds to. Bit 7 : 128/128 = 1.000000 Bit 6 : 64/128 = 0.500000 Bit 5 : 32/128 = 0.250000 Bit 4 : 16/128 = 0.125000 Bit 3 : 8/128 = 0.062500 Bit 2 : 4/128 = 0.031250 Bit 1 : 2/128 = 0.015625 Bit 0 : 1/128 = 0.0078125 Note that the output of the multiplier is 6 bits wide. It is possible to set the multiplier value here to a sufficiently large value to cause the multiplier result to be such that it can't be represented by a 6 bit value. In such a case, the multiplier output will be driven to 6'b111111.
  [7:0] TX_TXCC_P0POST_COEF_MULT_7_0 — Preset 0 post emphasis coefficient multiplier value : The value in this field specifies the multiplier value used to generate the preset 0 post emphasis coefficient value from the FS value. The following describes the multiplier value each bit in this field corresponds to. Bit 7 : 128/128 = 1.000000 Bit 6 : 64/128 = 0.500000 Bit 5 : 32/128 = 0.250000 Bit 4 : 16/128 = 0.125000 Bit 3 : 8/128 = 0.062500 Bit 2 : 4/128 = 0.031250 Bit 1 : 2/128 = 0.015625 Bit 0 : 1/128 = 0.0078125 Note that the output of the multiplier is 6 bits wide. It is possible to set the multiplier value here to a sufficiently large value to cause the multiplier result to be such that it can't be represented by a 6 bit value. In such a case, the multiplier output will be driven to 6'b111111.
0x40E4 WIZ16B8M4CT2_TX_TXCC_P3POST_COEF_MULT__TX_TXCC_P2POST_COEF_MULT reset 0x1B — Preset 2 post emphasis coefficient multiplier value register
  [7:0] TX_TXCC_P2POST_COEF_MULT_7_0 — Preset 2 post emphasis coefficient multiplier value : The value in this field specifies the multiplier value used to generate the preset 2 post emphasis coefficient value from the FS value. The following describes the multiplier value each bit in this field corresponds to. Bit 7 : 128/128 = 1.000000 Bit 6 : 64/128 = 0.500000 Bit 5 : 32/128 = 0.250000 Bit 4 : 16/128 = 0.125000 Bit 3 : 8/128 = 0.062500 Bit 2 : 4/128 = 0.031250 Bit 1 : 2/128 = 0.015625 Bit 0 : 1/128 = 0.0078125 Note that the output of the multiplier is 6 bits wide. It is possible to set the multiplier value here to a sufficiently large value to cause the multiplier result to be such that it can't be represented by a 6 bit value. In such a case, the multiplier output will be driven to 6'b111111.
0x40EC WIZ16B8M4CT2_TX_TXCC_P7POST_COEF_MULT__TX_TXCC_P6POST_COEF_MULT reset 0x1B0000 — Preset 6 post emphasis coefficient multiplier value register
  [23:16] TX_TXCC_P7POST_COEF_MULT_7_0 — Preset 7 post emphasis coefficient multiplier value : The value in this field specifies the multiplier value used to generate the preset 7 post emphasis coefficient value from the FS value. The following describes the multiplier value each bit in this field corresponds to. Bit 7 : 128/128 = 1.000000 Bit 6 : 64/128 = 0.500000 Bit 5 : 32/128 = 0.250000 Bit 4 : 16/128 = 0.125000 Bit 3 : 8/128 = 0.062500 Bit 2 : 4/128 = 0.031250 Bit 1 : 2/128 = 0.015625 Bit 0 : 1/128 = 0.0078125 Note that the output of the multiplier is 6 bits wide. It is possible to set the multiplier value here to a sufficiently large value to cause the multiplier result to be such that it can't be represented by a 6 bit value. In such a case, the multiplier output will be driven to 6'b111111.
0x40F0 WIZ16B8M4CT2_TX_TXCC_P9POST_COEF_MULT__TX_TXCC_P8POST_COEF_MULT reset 0x10 — Preset 8 post emphasis coefficient multiplier value register
  [7:0] TX_TXCC_P8POST_COEF_MULT_7_0 — Preset 8 post emphasis coefficient multiplier value : The value in this field specifies the multiplier value used to generate the preset 8 post emphasis coefficient value from the FS value. The following describes the multiplier value each bit in this field corresponds to. Bit 7 : 128/128 = 1.000000 Bit 6 : 64/128 = 0.500000 Bit 5 : 32/128 = 0.250000 Bit 4 : 16/128 = 0.125000 Bit 3 : 8/128 = 0.062500 Bit 2 : 4/128 = 0.031250 Bit 1 : 2/128 = 0.015625 Bit 0 : 1/128 = 0.0078125 Note that the output of the multiplier is 6 bits wide. It is possible to set the multiplier value here to a sufficiently large value to cause the multiplier result to be such that it can't be represented by a 6 bit value. In such a case, the multiplier output will be driven to 6'b111111.
